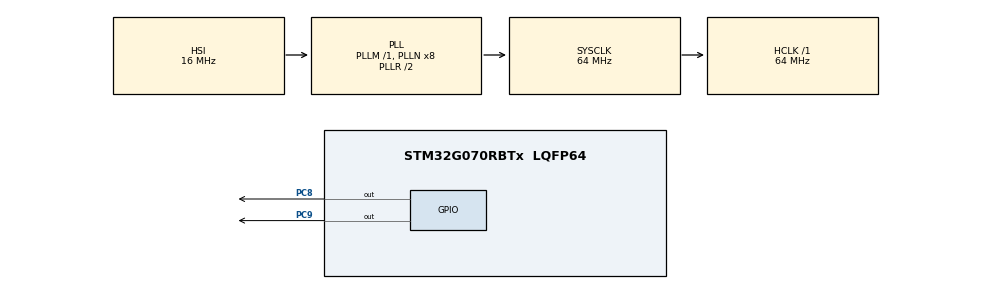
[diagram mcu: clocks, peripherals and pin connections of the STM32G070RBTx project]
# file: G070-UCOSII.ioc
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Mcu.Family=STM32G0
Mcu.Name=STM32G070RBTx
Mcu.Package=LQFP64
NVIC.TIM3_IRQn=true\:0\:0\:false\:false\:true\:true\:true
PA13.Mode=Serial_Wire
PA13.Signal=SYS_SWDIO
PA14-BOOT0.Mode=Serial_Wire
PA14-BOOT0.Signal=SYS_SWCLK
PC8.Signal=GPIO_Output
PC9.Signal=GPIO_Output
ProjectManager.HeapSize=0x200
ProjectManager.StackSize=0x400
ProjectManager.TargetToolchain=MDK-ARM V5.27
RCC.ADCFreq_Value=64000000
RCC.AHBFreq_Value=64000000
RCC.CortexFreq_Value=64000000
RCC.EXTERNAL_CLOCK_VALUE=48000
RCC.HCLKFreq_Value=64000000
RCC.HSE_VALUE=8000000
RCC.HSI_VALUE=16000000
RCC.LSE_VALUE=32768
RCC.SYSCLKFreq_VALUE=64000000
RCC.SYSCLKSource=RCC_SYSCLKSOURCE_PLLCLK
RCC.VCOOutputFreq_Value=128000000
TIM3.Period=999
TIM3.Prescaler=63
VP_SYS_VS_DBSignals.Mode=DisableDeadBatterySignals
VP_TIM3_VS_ClockSourceINT.Mode=Internal
board=custom

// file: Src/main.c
/* USER CODE BEGIN Header */
/***************************************************************************//**
  文件名称: main.c
  作　  者: Zhengyu https://gzwelink.taobao.com
  版    本: V1.0.0
  日  　期: 2020年1月1日
	适用硬件:MINI-G070RBT6 开发板
  * 郑重声明：
  * 此文件只用于提供开发参考
*******************************************************************************/
/* USER CODE END Header */

#include "main.h"
#include "tim.h"
#include "gpio.h"
#include "ucos_ii.h"

/* USER CODE BEGIN Includes */
static   OS_STK   App_Task_LED1_Stk[APP_TASK_LED1_STK_SIZE];
static   OS_STK   App_Task_LED2_Stk[APP_TASK_LED2_STK_SIZE];

/* 任务函数 ------------------------------------------------------------------*/
static  void  App_Task_LED1(void* p_arg);
static  void  App_Task_LED2(void* p_arg);
;/***************************************************************************************
;* 函数名称: App_Task_LED1
;*
;* 功能描述: LED1闪烁，周期500ms
;*
;* 参    数: None
;*
;* 返 回 值: None
;*
;* 作　  者: Zhengyu https://gzwelink.taobao.com
;* 日  　期: 2020年1月1日
;*----------------------------------------------------------------------------------------
;*****************************************************************************************/
void App_Task_LED1(void* pdata)
{
    pdata = pdata;

    for (;;)
    {
				 OSTimeDly(250);
         HAL_GPIO_TogglePin(GPIOC, GPIO_PIN_8);
    }

}

;/***************************************************************************************
;* 函数名称: App_Task_LED2
;*
;* 功能描述: LED2闪烁，周期1000ms
;*
;* 参    数: None
;*
;* 返 回 值: None
;*
;* 作　  者: Zhengyu https://gzwelink.taobao.com
;* 日  　期: 2020年1月1日
;*----------------------------------------------------------------------------------------
;*****************************************************************************************/
void App_Task_LED2(void* pdata)
{
    pdata = pdata;

    for (;;)
    {
         OSTimeDly(500);
         HAL_GPIO_TogglePin(GPIOC, GPIO_PIN_9);
    }
}
/* USER CODE END Includes */

void SystemClock_Config(void);

int main(void)
{
  /* USER CODE BEGIN 1 */
INT8U os_err;
  /* USER CODE END 1 */

  /* MCU Configuration--------------------------------------------------------*/

  /* Reset of all peripherals, Initializes the Flash interface and the Systick. */
  HAL_Init();

  /* Configure the system clock */
  SystemClock_Config();

  /* Initialize all configured peripherals */
  MX_GPIO_Init();
  MX_TIM3_Init();
  /* USER CODE BEGIN 2 */
	OSInit();
	OS_CPU_SysTickInit();

	//创建任务1:LED1
	os_err = OSTaskCreate( App_Task_LED1,
												(void *) 0,
												(OS_STK *) &App_Task_LED1_Stk[APP_TASK_LED1_STK_SIZE - 1],
												(INT8U) APP_TASK_LED1_PRIO);

		//创建任务2:LED2
	os_err = OSTaskCreate( App_Task_LED2,
												(void*) 0,
												(OS_STK*) &App_Task_LED2_Stk[APP_TASK_LED2_STK_SIZE - 1],
												(INT8U ) APP_TASK_LED2_PRIO);

	os_err = os_err;

	OSStart ();
  /* USER CODE END 2 */

}

void SystemClock_Config(void)
{
  RCC_OscInitTypeDef RCC_OscInitStruct = {0};
  RCC_ClkInitTypeDef RCC_ClkInitStruct = {0};

  /** Configure the main internal regulator output voltage
  */
  HAL_PWREx_ControlVoltageScaling(PWR_REGULATOR_VOLTAGE_SCALE1);
  /** Initializes the CPU, AHB and APB busses clocks
  */
  RCC_OscInitStruct.OscillatorType = RCC_OSCILLATORTYPE_HSI;
  RCC_OscInitStruct.HSIState = RCC_HSI_ON;
  RCC_OscInitStruct.HSIDiv = RCC_HSI_DIV1;
  RCC_OscInitStruct.HSICalibrationValue = RCC_HSICALIBRATION_DEFAULT;
  RCC_OscInitStruct.PLL.PLLState = RCC_PLL_ON;
  RCC_OscInitStruct.PLL.PLLSource = RCC_PLLSOURCE_HSI;
  RCC_OscInitStruct.PLL.PLLM = RCC_PLLM_DIV1;
  RCC_OscInitStruct.PLL.PLLN = 8;
  RCC_OscInitStruct.PLL.PLLP = RCC_PLLP_DIV2;
  RCC_OscInitStruct.PLL.PLLR = RCC_PLLR_DIV2;
  if (HAL_RCC_OscConfig(&RCC_OscInitStruct) != HAL_OK)
  {
    Error_Handler();
  }
  /** Initializes the CPU, AHB and APB busses clocks
  */
  RCC_ClkInitStruct.ClockType = RCC_CLOCKTYPE_HCLK|RCC_CLOCKTYPE_SYSCLK
                              |RCC_CLOCKTYPE_PCLK1;
  RCC_ClkInitStruct.SYSCLKSource = RCC_SYSCLKSOURCE_PLLCLK;
  RCC_ClkInitStruct.AHBCLKDivider = RCC_SYSCLK_DIV1;
  RCC_ClkInitStruct.APB1CLKDivider = RCC_HCLK_DIV1;

  if (HAL_RCC_ClockConfig(&RCC_ClkInitStruct, FLASH_LATENCY_2) != HAL_OK)
  {
    Error_Handler();
  }
}

void Error_Handler(void)
{
}

/************************ (C) COPYRIGHT STMicroelectronics *****END OF FILE****/
